# RN831X_RN861X_MCU register map
File version: v0.0.1
CPU: RN831X_RN861X_MCU r1p0, little endian, MPU, no FPU
Registers are 32-bit, read-write, reset 0x0 unless marked. A register's access mark holds for its fields unless they carry their own. Offsets are from the block's base; [hi:lo] are bit positions; {n}, {i} and the like mark numbered series.

## LSRX_CORE0 — LSRX Module core0
Base 0x2002C000
Same registers: LSRX_CORE1 0xA002C000
0x00 FTOP access not given reset 0x800A8000 — LSRX identify frame header register
  [31:0] FTOP — LSRX identify frame header bits
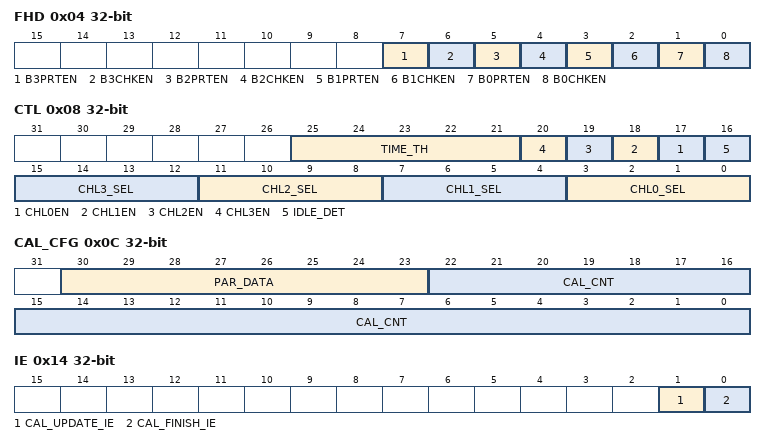
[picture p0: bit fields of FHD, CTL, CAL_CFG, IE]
0x04 FHD — LSRX identify frame header enable register
  [7] B3PRTEN — Fourth byte parity function of frame enable bit
  [6] B3CHKEN — Fourth byte of check funcstion of frame header enable bit
  [5] B2PRTEN — Third byte parity function of frame enable bit
  [4] B2CHKEN — Third byte of check funcstion of frame header enable bit
  [3] B1PRTEN — Second byte parity function of frame enable bit
  [2] B1CHKEN — Second byte of check funcstion of frame header enable bit
  [1] B0PRTEN — First byte parity function of frame enable bit
  [0] B0CHKEN — First byte check funcstion of frame header enable bit
0x08 CTL — LSRX control register
  [25:21] TIME_TH — Threshold time config bits
  [n+17] CHL{n}EN (n=0..3) — Channel{n} receive enable bit
  [16] IDLE_DET — LSRX idle check enable bit
  [4n+3:4n] CHL{n}_SEL (n=0..3) — Channel{n} select bits
    {v}=UART{v} (Channel select UART{v}) (v=0..7)
0x0C CAL_CFG — Calibration configuration register
  [30:23] PAR_DATA — Parity data bits of calibration wave
  [22:0] CAL_CNT — Calibration wave output cycle config bits
0x10 EN access not given — LSRX enable register
  [0] EN — LSRX enable bit
0x14 IE — LSRX interrupt enable register
  [1] CAL_UPDATE_IE — Calibration update interrupt enable bit
  [0] CAL_FINISH_IE — Calibration wave transmit finish enable bit
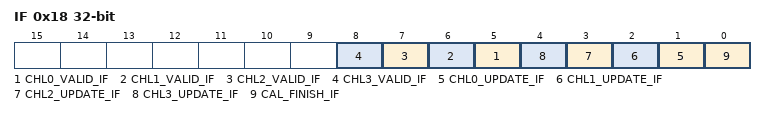
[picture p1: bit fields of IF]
0x18 IF — LSRX interrupt flag register
  [n+5] CHL{n}_VALID_IF write-1-clears (n=0..3) — Channel{n} receive timeout flag bit
  [n+1] CHL{n}_UPDATE_IF write-1-clears (n=0..3) — Channel{n} update interrupt flag bit
  [0] CAL_FINISH_IF write-1-clears — Calibration wave transmit finish interrupt flag bit
{0x1C+4i} CH{i}FH_TIME access not given (i=0..3) — Channel{i} frame header time register
  [24:0] CH{i}FH_TIME — Channel{i} frame header time bits

## LVDCMP_CORE0 — LVD and CMP module
Base 0x200BC000
Same registers: LVDCMP_CORE1 0xA00BC000
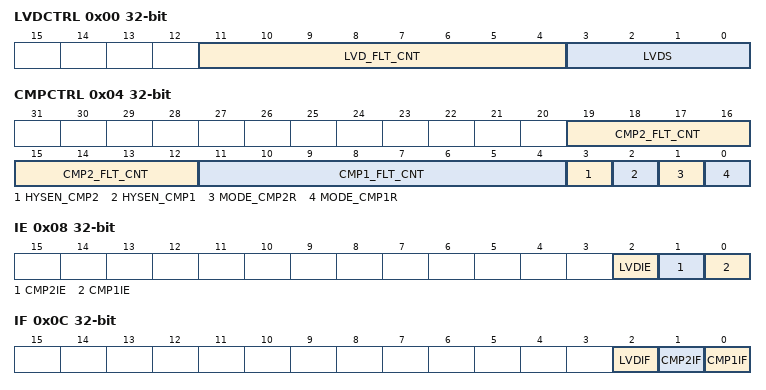
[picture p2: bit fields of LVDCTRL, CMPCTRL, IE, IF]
0x00 LVDCTRL access not given — LVD Control Register
  [11:4] LVD_FLT_CNT — The filter can be configured from 0 to 255 clock cycles. Setting to 0 disables the filter.
  [3:0] LVDS — LVD threshold voltage set bits
    0=1P9 (select 1.9 as LVD Vil, 2.0 as LVD Vih); 1=2P1 (select 2.1 as LVD Vil, 2.2 as LVD Vih); 2=2P3 (select 2.3 as LVD Vil, 2.4 as LVD Vih); 3=2P5 (select 2.5 as LVD Vil, 2.6 as LVD Vih); 4=2P7 (select 2.7 as LVD Vil, 2.8 as LVD Vih); 5=2P9 (select 2.9 as LVD Vil, 3.0 as LVD Vih); 6=3P1 (select 3.1 as LVD Vil, 3.2 as LVD Vih); 7=3P3 (select 3.3 as LVD Vil, 3.4 as LVD Vih); 8=3P5 (select 3.5 as LVD Vil, 3.6 as LVD Vih); 9=3P7 (select 3.7 as LVD Vil, 3.8 as LVD Vih); 10=3P9 (select 3.9 as LVD Vil, 4.0 as LVD Vih); 11=4P1 (select 4.1 as LVD Vil, 4.2 as LVD Vih); 12=4P3 (select 4.3 as LVD Vil, 4.4 as LVD Vih); 13=4P5 (select 4.5 as LVD Vil, 4.6 as LVD Vih); 14=4P7 (select 4.7 as LVD Vil, 4.8 as LVD Vih); 15=LVDIN (select 1.25 as LVD Vil, 1.45 as LVD Vih ,and compare with voltage found on LVDIN pin)
0x04 CMPCTRL access not given — CMP Control Register
  [19:12] CMP2_FLT_CNT — The filter can be configured from 0 to 255 clock cycles. Setting to 0 disables the filter.
  [11:4] CMP1_FLT_CNT — The filter can be configured from 0 to 255 clock cycles. Setting to 0 disables the filter.
  [3] HYSEN_CMP2 — CMP2 hysteresis switch bit
  [2] HYSEN_CMP1 — CMP1 hysteresis switch bit
  [1] MODE_CMP2R — switch bit of CMP2 internal 600K simpling resistor(=1 register off, =0 register on)
  [0] MODE_CMP1R — switch bit of CMP1 internal 600K simpling resistor(=1 register off, =0 register on)
0x08 IE access not given — CMP, LVD Interrupt Enable Register
  [2] LVDIE — LVD interrupt enable bit
  [1] CMP2IE — comparator No.2 interrupt enable bit
  [0] CMP1IE — comparator No.1 interrupt enable bit
0x0C IF — CMP, LVD Interrupt Flag Register
  [2] LVDIF write-1-clears — LVD interrupt flag
  [1] CMP2IF write-1-clears — comparator No.2 interrupt flag
  [0] CMP1IF write-1-clears — comparator NO.1 interrupt flag
0x10 LVDPWD access not given — LVD Power Down Register
  [31:0] LVDPWD — LVD Power Down Register bits
    0x55AAAA55=PWDN (LVD off,Power down); 0=EN (LVD enable)
0x14 CMP2PWD access not given — CMP2 Power Down Register
  [31:0] CMP2PWD — CMP2 Power Down Register bits
    0xAA5555AA=PWDN (cmp off,Power down); 0=EN (cmp enable)
0x18 CMP1PWD access not given — CMP1 Power Down Register
  [31:0] CMP1PWD — CMP1 Power Down Register bits
    0xA5A55A5A=PWDN (cmp off,Power down); 0=EN (cmp enable)
